AUTOSAR XML (schema 321)
package /ComponentType
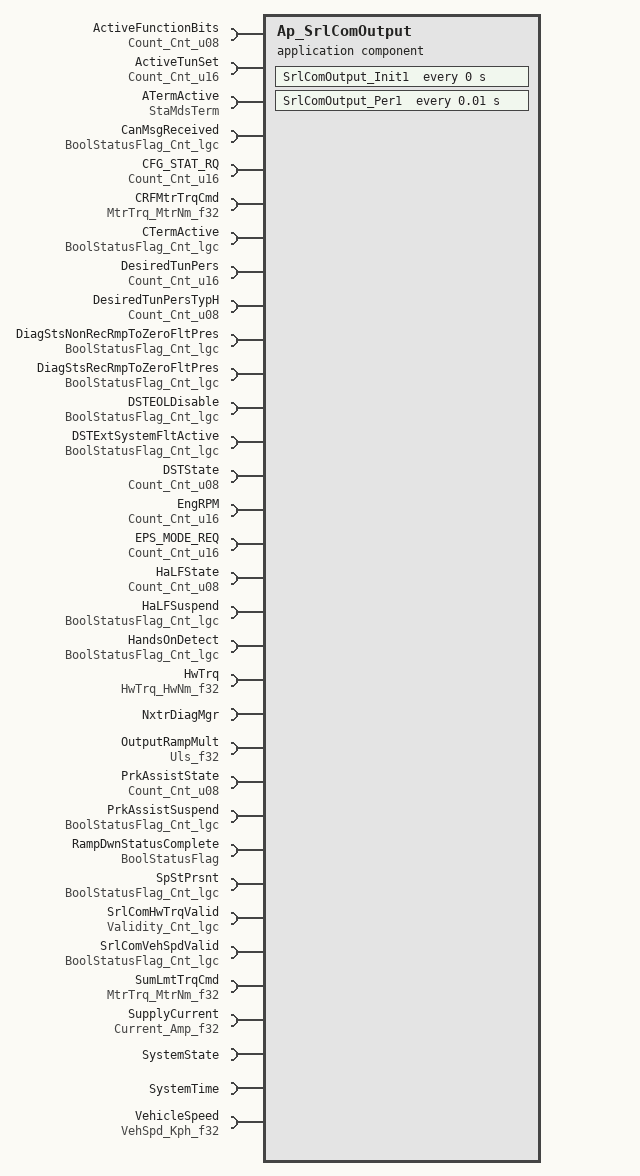
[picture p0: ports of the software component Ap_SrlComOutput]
  application software component type Ap_SrlComOutput
    33 x require port:
      ActiveFunctionBits: unqueued-receiver-com-spec{data-element=Cnt_u08, handle-invalid=DONT-INVALIDATE, init-value=D_ZERO_CNT_U8}, required-interface=Count_Cnt_u08
      ActiveTunSet: unqueued-receiver-com-spec{data-element=Cnt_u16, handle-invalid=DONT-INVALIDATE, init-value=D_ZERO_CNT_U16}, required-interface=Count_Cnt_u16
      ATermActive: unqueued-receiver-com-spec{data-element=Cnt_lgc, handle-invalid=DONT-INVALIDATE, init-value=D_TRUE_CNT_LGC}, required-interface=StaMdsTerm
      CanMsgReceived: unqueued-receiver-com-spec{data-element=Cnt_lgc, handle-invalid=DONT-INVALIDATE, init-value=D_FALSE_CNT_LGC}, required-interface=BoolStatusFlag_Cnt_lgc
      CFG_STAT_RQ: unqueued-receiver-com-spec{data-element=Cnt_u16, handle-invalid=DONT-INVALIDATE, init-value=D_ZERO_CNT_U16}, required-interface=Count_Cnt_u16
      CRFMtrTrqCmd: unqueued-receiver-com-spec{data-element=MtrNm_f32, handle-invalid=DONT-INVALIDATE, init-value=D_ZERO_ULS_F32}, required-interface=MtrTrq_MtrNm_f32
      CTermActive: unqueued-receiver-com-spec{data-element=Cnt_lgc, handle-invalid=DONT-INVALIDATE, init-value=D_FALSE_CNT_LGC}, required-interface=BoolStatusFlag_Cnt_lgc
      DesiredTunPers: unqueued-receiver-com-spec{data-element=Cnt_u16, handle-invalid=DONT-INVALIDATE, init-value=D_ZERO_CNT_U16}, required-interface=Count_Cnt_u16
      DesiredTunPersTypH: unqueued-receiver-com-spec{data-element=Cnt_u08, handle-invalid=DONT-INVALIDATE, init-value=D_ZERO_CNT_U8}, required-interface=Count_Cnt_u08
      DiagStsNonRecRmpToZeroFltPres: unqueued-receiver-com-spec{data-element=Cnt_lgc, handle-invalid=DONT-INVALIDATE, init-value=D_FALSE_CNT_LGC}, required-interface=BoolStatusFlag_Cnt_lgc
      DiagStsRecRmpToZeroFltPres: unqueued-receiver-com-spec{data-element=Cnt_lgc, handle-invalid=DONT-INVALIDATE, init-value=D_FALSE_CNT_LGC}, required-interface=BoolStatusFlag_Cnt_lgc
      DSTEOLDisable: unqueued-receiver-com-spec{data-element=Cnt_lgc, handle-invalid=DONT-INVALIDATE, init-value=D_FALSE_CNT_LGC}, required-interface=BoolStatusFlag_Cnt_lgc
      DSTExtSystemFltActive: unqueued-receiver-com-spec{data-element=Cnt_lgc, handle-invalid=DONT-INVALIDATE, init-value=D_FALSE_CNT_LGC}, required-interface=BoolStatusFlag_Cnt_lgc
      DSTState: unqueued-receiver-com-spec{data-element=Cnt_u08, handle-invalid=DONT-INVALIDATE, init-value=D_ZERO_CNT_U8}, required-interface=Count_Cnt_u08
      EngRPM: unqueued-receiver-com-spec{data-element=Cnt_u16, handle-invalid=DONT-INVALIDATE, init-value=D_ONE_CNT_U16}, required-interface=Count_Cnt_u16
      EPS_MODE_REQ: unqueued-receiver-com-spec{data-element=Cnt_u16, handle-invalid=DONT-INVALIDATE, init-value=D_ZERO_CNT_U16}, required-interface=Count_Cnt_u16
      HaLFState: unqueued-receiver-com-spec{data-element=Cnt_u08, handle-invalid=DONT-INVALIDATE, init-value=D_ZERO_CNT_U8}, required-interface=Count_Cnt_u08
      HaLFSuspend: unqueued-receiver-com-spec{data-element=Cnt_lgc, handle-invalid=DONT-INVALIDATE, init-value=D_FALSE_CNT_LGC}, required-interface=BoolStatusFlag_Cnt_lgc
      HandsOnDetect: unqueued-receiver-com-spec{data-element=Cnt_lgc, handle-invalid=DONT-INVALIDATE, init-value=D_FALSE_CNT_LGC}, required-interface=BoolStatusFlag_Cnt_lgc
      HwTrq: unqueued-receiver-com-spec{data-element=HwNm_f32, handle-invalid=DONT-INVALIDATE, init-value=D_ZERO_ULS_F32}, required-interface=HwTrq_HwNm_f32
      NxtrDiagMgr: required-com-specs=[GetNTCActive, GetNTCFailed, GetNTCStatus, SetNTCStatus], required-interface=NxtrDiagMgr
      OutputRampMult: unqueued-receiver-com-spec{data-element=Uls_f32, handle-invalid=DONT-INVALIDATE, init-value=D_ZERO_ULS_F32}, required-interface=Uls_f32
      PrkAssistState: unqueued-receiver-com-spec{data-element=Cnt_u08, handle-invalid=DONT-INVALIDATE, init-value=D_ZERO_CNT_U8}, required-interface=Count_Cnt_u08
      PrkAssistSuspend: unqueued-receiver-com-spec{data-element=Cnt_lgc, handle-invalid=DONT-INVALIDATE, init-value=D_FALSE_CNT_LGC}, required-interface=BoolStatusFlag_Cnt_lgc
      RampDwnStatusComplete: unqueued-receiver-com-spec{data-element=Cnt_lgc, handle-invalid=DONT-INVALIDATE, init-value=D_FALSE_CNT_LGC}, required-interface=BoolStatusFlag
      SpStPrsnt: unqueued-receiver-com-spec{data-element=Cnt_lgc, handle-invalid=DONT-INVALIDATE, init-value=D_FALSE_CNT_LGC}, required-interface=BoolStatusFlag_Cnt_lgc
      SrlComHwTrqValid: unqueued-receiver-com-spec{data-element=Cnt_lgc, handle-invalid=DONT-INVALIDATE, init-value=D_FALSE_CNT_LGC}, required-interface=Validity_Cnt_lgc
      SrlComVehSpdValid: unqueued-receiver-com-spec{data-element=Cnt_lgc, handle-invalid=DONT-INVALIDATE, init-value=D_FALSE_CNT_LGC}, required-interface=BoolStatusFlag_Cnt_lgc
      SumLmtTrqCmd: unqueued-receiver-com-spec{data-element=MtrNm_f32, handle-invalid=DONT-INVALIDATE, init-value=D_ZERO_ULS_F32}, required-interface=MtrTrq_MtrNm_f32
      SupplyCurrent: unqueued-receiver-com-spec{data-element=Amp_f32, handle-invalid=DONT-INVALIDATE, init-value=D_ZERO_ULS_F32}, required-interface=Current_Amp_f32
      SystemState: required-interface=SystemState
      SystemTime: required-interface=SystemTime
        required-com-specs:
          DtrmnElapsedTime_mS_u16
          DtrmnElapsedTime_mS_u32
          DtrmnElapsedTime_uS_u16
          DtrmnElapsedTime_uS_u32
          GetSystemTime_mS_u32
          GetSystemTime_uS_u32
      VehicleSpeed: unqueued-receiver-com-spec{data-element=Kph_f32, handle-invalid=DONT-INVALIDATE, init-value=D_ZERO_ULS_F32}, required-interface=VehSpd_Kph_f32
  internal behavior Ap_SrlComOutput_InternalBehavior: component=Ap_SrlComOutput
    timing event SrlComOutput_Init1_InitEvent: start-on-event=SrlComOutput_Init1, period=0
    timing event TMT_SrlComOutput_Per1: start-on-event=SrlComOutput_Per1, period=0.01
    port-api-options:
      enable-take-address=false, indirect-api=false, port=ActiveFunctionBits
      enable-take-address=false, indirect-api=false, port=ActiveTunSet
      enable-take-address=false, indirect-api=false, port=ATermActive
      enable-take-address=false, indirect-api=false, port=CanMsgReceived
      enable-take-address=false, indirect-api=false, port=CFG_STAT_RQ
      enable-take-address=false, indirect-api=false, port=CRFMtrTrqCmd
      enable-take-address=false, indirect-api=false, port=CTermActive
      enable-take-address=false, indirect-api=false, port=DesiredTunPers
      enable-take-address=false, indirect-api=false, port=DesiredTunPersTypH
      enable-take-address=false, indirect-api=false, port=DiagStsNonRecRmpToZeroFltPres
      enable-take-address=false, indirect-api=false, port=DiagStsRecRmpToZeroFltPres
      enable-take-address=false, indirect-api=false, port=DSTEOLDisable
      enable-take-address=false, indirect-api=false, port=DSTExtSystemFltActive
      enable-take-address=false, indirect-api=false, port=DSTState
      enable-take-address=false, indirect-api=false, port=EngRPM
      enable-take-address=false, indirect-api=false, port=EPS_MODE_REQ
      enable-take-address=false, indirect-api=false, port=HaLFState
      enable-take-address=false, indirect-api=false, port=HaLFSuspend
      enable-take-address=false, indirect-api=false, port=HandsOnDetect
      enable-take-address=false, indirect-api=false, port=HwTrq
      enable-take-address=false, indirect-api=false, port=NxtrDiagMgr
      enable-take-address=false, indirect-api=false, port=OutputRampMult
      enable-take-address=false, indirect-api=false, port=PrkAssistState
      enable-take-address=false, indirect-api=false, port=PrkAssistSuspend
      enable-take-address=false, indirect-api=false, port=RampDwnStatusComplete
      enable-take-address=false, indirect-api=false, port=SpStPrsnt
      enable-take-address=false, indirect-api=false, port=SrlComHwTrqValid
      enable-take-address=false, indirect-api=false, port=SrlComVehSpdValid
      enable-take-address=false, indirect-api=false, port=SumLmtTrqCmd
      enable-take-address=false, indirect-api=false, port=SupplyCurrent
      enable-take-address=false, indirect-api=false, port=SystemState
      enable-take-address=false, indirect-api=false, port=SystemTime
      enable-take-address=false, indirect-api=false, port=VehicleSpeed
    runnable SrlComOutput_Init1
    runnable SrlComOutput_Per1
      30 x data receive point:
        REC_ActiveFunctionBits_Cnt_u08: data-element=ActiveFunctionBits.Cnt_u08
        REC_ActiveTunSet_Cnt_u16: data-element=ActiveTunSet.Cnt_u16
        REC_ATermActive_Cnt_lgc: data-element=ATermActive.Cnt_lgc
        REC_CanMsgReceived_Cnt_lgc: data-element=CanMsgReceived.Cnt_lgc
        REC_CFG_STAT_RQ_Cnt_u16: data-element=CFG_STAT_RQ.Cnt_u16
        REC_CRFMtrTrqCmd_MtrNm_f32: data-element=CRFMtrTrqCmd.MtrNm_f32
        REC_CTermActive_Cnt_lgc: data-element=CTermActive.Cnt_lgc
        REC_DesiredTunPers_Cnt_u16: data-element=DesiredTunPers.Cnt_u16
        REC_DesiredTunPersTypH_Cnt_u08: data-element=DesiredTunPersTypH.Cnt_u08
        REC_DiagStsNonRecRmpToZeroFltPres_Cnt_lgc: data-element=DiagStsNonRecRmpToZeroFltPres.Cnt_lgc
        REC_DiagStsRecRmpToZeroFltPres_Cnt_lgc: data-element=DiagStsRecRmpToZeroFltPres.Cnt_lgc
        REC_DSTEOLDisable_Cnt_lgc: data-element=DSTEOLDisable.Cnt_lgc
        REC_DSTExtSystemFltActive_Cnt_lgc: data-element=DSTExtSystemFltActive.Cnt_lgc
        REC_DSTState_Cnt_u08: data-element=DSTState.Cnt_u08
        REC_EngRPM_Cnt_u16: data-element=EngRPM.Cnt_u16
        REC_EPS_MODE_REQ_Cnt_u16: data-element=EPS_MODE_REQ.Cnt_u16
        REC_HaLFState_Cnt_u08: data-element=HaLFState.Cnt_u08
        REC_HaLFSuspend_Cnt_lgc: data-element=HaLFSuspend.Cnt_lgc
        REC_HandsOnDetect_Cnt_lgc: data-element=HandsOnDetect.Cnt_lgc
        REC_HwTrq_HwNm_f32: data-element=HwTrq.HwNm_f32
        REC_OutputRampMult_Uls_f32: data-element=OutputRampMult.Uls_f32
        REC_PrkAssistState_Cnt_u08: data-element=PrkAssistState.Cnt_u08
        REC_PrkAssistSuspend_Cnt_lgc: data-element=PrkAssistSuspend.Cnt_lgc
        REC_RampDwnStatusComplete_Cnt_lgc: data-element=RampDwnStatusComplete.Cnt_lgc
        REC_SpStPrsnt_Cnt_lgc: data-element=SpStPrsnt.Cnt_lgc
        REC_SrlComHwTrqValid_Cnt_lgc: data-element=SrlComHwTrqValid.Cnt_lgc
        REC_SrlComVehSpdValid_Cnt_lgc: data-element=SrlComVehSpdValid.Cnt_lgc
        REC_SumLmtTrqCmd_MtrNm_f32: data-element=SumLmtTrqCmd.MtrNm_f32
        REC_SupplyCurrent_Amp_f32: data-element=SupplyCurrent.Amp_f32
        REC_VehicleSpeed_Kph_f32: data-element=VehicleSpeed.Kph_f32
      sync call SC_NxtrDiagMgr_GetNTCFailed: operation=NxtrDiagMgr.GetNTCFailed, timeout=0
      sync call SC_SystemTime_DtrmnElapsedTime_mS_u32: operation=SystemTime.DtrmnElapsedTime_mS_u32, timeout=0
      sync call SC_SystemTime_GetSystemTime_mS_u32: operation=SystemTime.GetSystemTime_mS_u32, timeout=0
  swc implementation Ap_SrlComOutput_Implementation: behavior=Ap_SrlComOutput_InternalBehavior
    code-descriptors:
      code Code: type=SRC
